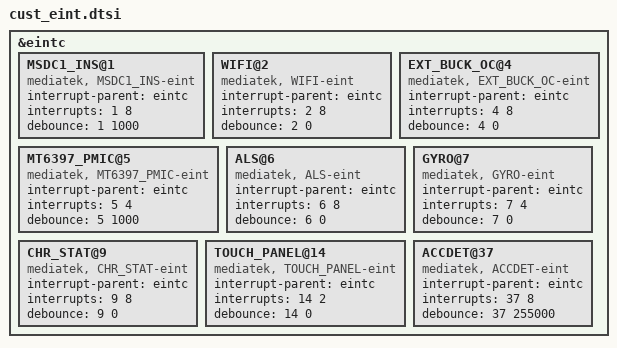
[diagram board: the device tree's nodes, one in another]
/*
 * Generated by MTK SP Drv_CodeGen Version 03.13.6  for MT8173. Copyright MediaTek Inc. (C) 2013.
 * Mon Nov 10 18:10:24 2014
 * Do Not Modify the File.
 */

/*************************
 * EINT DTSI File
*************************/

&eintc {
	MSDC1_INS@1 {
		compatible = "mediatek, MSDC1_INS-eint";
		interrupt-parent = <&eintc>;
		interrupts = <1 8>;
		debounce = <1 1000>;
	};

	WIFI@2 {
		compatible = "mediatek, WIFI-eint";
		interrupt-parent = <&eintc>;
		interrupts = <2 8>;
		debounce = <2 0>;
	};

	EXT_BUCK_OC@4 {
		compatible = "mediatek, EXT_BUCK_OC-eint";
		interrupt-parent = <&eintc>;
		interrupts = <4 8>;
		debounce = <4 0>;
	};

	MT6397_PMIC@5 {
		compatible = "mediatek, MT6397_PMIC-eint";
		interrupt-parent = <&eintc>;
		interrupts = <5 4>;
		debounce = <5 1000>;
	};

	ALS@6 {
		compatible = "mediatek, ALS-eint";
		interrupt-parent = <&eintc>;
		interrupts = <6 8>;
		debounce = <6 0>;
	};

	GYRO@7 {
		compatible = "mediatek, GYRO-eint";
		interrupt-parent = <&eintc>;
		interrupts = <7 4>;
		debounce = <7 0>;
	};

	CHR_STAT@9 {
		compatible = "mediatek, CHR_STAT-eint";
		interrupt-parent = <&eintc>;
		interrupts = <9 8>;
		debounce = <9 0>;
	};

	TOUCH_PANEL@14 {
		compatible = "mediatek, TOUCH_PANEL-eint";
		interrupt-parent = <&eintc>;
		interrupts = <14 2>;
		debounce = <14 0>;
	};

	ACCDET@37 {
		compatible = "mediatek, ACCDET-eint";
		interrupt-parent = <&eintc>;
		interrupts = <37 8>;
		debounce = <37 255000>;
	};

};
